# CM_PER register map
Vendor: Texas Instruments
Peripheral module from a debugger description file (folder am437x).
Registers are 32-bit, access per field, no defined reset value unless marked. A register's access mark holds for its fields unless they carry their own. Offsets are as the file gives them; lines under a group give offsets from that group; [hi:lo] are bit positions; {n}, {i} and the like mark numbered series; 'fields as' and 'values as' point back to an identical list; <NAME> marks a mode.

## CM_PER
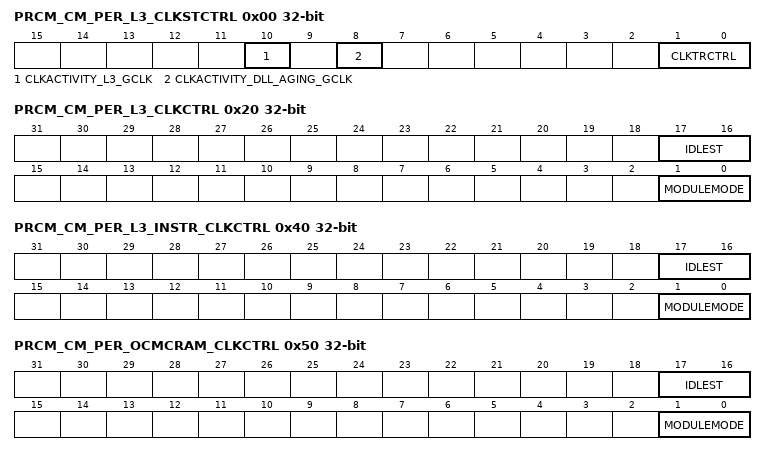
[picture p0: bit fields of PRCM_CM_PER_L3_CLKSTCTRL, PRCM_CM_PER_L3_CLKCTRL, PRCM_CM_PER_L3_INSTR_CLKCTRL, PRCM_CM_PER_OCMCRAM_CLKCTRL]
0x00 PRCM_CM_PER_L3_CLKSTCTRL — This register enables the domain power state transition. It controls the SW supervised clock domain state transition between ON-ACTIVE and ON-INACTIVE states. It also hold one status bit per clock input of the domain.
  [10] CLKACTIVITY_L3_GCLK ro — This field indicates the state of the L3_GCLK clock in the domain.
    1=en_2_0x1 (Corresponding clock is active); 0=en_1_0x0 (Corresponding clock is gated)
  [8] CLKACTIVITY_DLL_AGING_GCLK ro — This field indicates the state of the DLL_AGING_GCLK clock in the domain.
    values as CLKACTIVITY_L3_GCLK
  [1:0] CLKTRCTRL rw — Controls the clock state transition of the L3 clock domain.
    3=en_4_0x3 (Reserved); 2=en_3_0x2 (SW_WKUP: Start a software forced wake-up transition on the domain.); 1=en_2_0x1 (SW_SLEEP: Start a software forced sleep transition on the domain.); 0=en_1_0x0 (NO_SLEEP: Sleep transition cannot be initiated. Wakeup transition may however occur.)
0x20 PRCM_CM_PER_L3_CLKCTRL — This register manages the L3 Interconnect clocks.
  [17:16] IDLEST ro — Module idle status.
    3=en_4_0x3 (Module is disabled and cannot be accessed); 2=en_3_0x2 (Module is in Idle mode (only OCP part). It is functional if using separate functional clock); 1=en_2_0x1 (Module is performing transition: wakeup, or sleep, or sleep abortion); 0=en_1_0x0 (Module is fully functional, including OCP)
  [1:0] MODULEMODE rw — Control the way mandatory clocks are managed.
    3=en_4_0x3 (Reserved); 2=en_3_0x2 (Module is explicitly enabled. Interface clock (if not used for functions) may be gated according to the clock domain state. Functional clocks are guarantied to stay present. As long as in this configuration, power domain sleep transition cannot happen.); 1=en_2_0x1 (Reserved); 0=en_1_0x0 (Module is disable by SW. Any OCP access to module results in an error, except if resulting from a module wakeup (asynchronous wakeup).)
0x40 PRCM_CM_PER_L3_INSTR_CLKCTRL — This register manages the L3 INSTR clocks.
  fields as PRCM_CM_PER_L3_CLKCTRL
0x50 PRCM_CM_PER_OCMCRAM_CLKCTRL — This register manages the OCMC clocks.
  fields as PRCM_CM_PER_L3_CLKCTRL
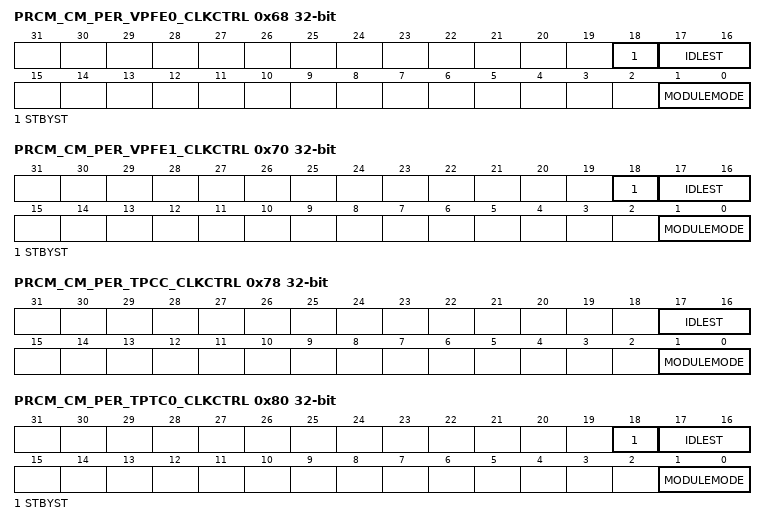
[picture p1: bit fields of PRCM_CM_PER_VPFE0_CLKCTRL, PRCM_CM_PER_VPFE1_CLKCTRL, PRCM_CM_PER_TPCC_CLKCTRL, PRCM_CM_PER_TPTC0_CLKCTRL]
0x68 PRCM_CM_PER_VPFE0_CLKCTRL — This register manages the VPFE0 clocks.
  [18] STBYST ro — Module standby status.
    1=en_2_0x1 (Module is in standby); 0=en_1_0x0 (Module is functional (not in standby))
  [17:16] IDLEST ro — Module idle status.
    values as PRCM_CM_PER_L3_CLKCTRL.IDLEST
  [1:0] MODULEMODE rw — Control the way mandatory clocks are managed.
    values as PRCM_CM_PER_L3_CLKCTRL.MODULEMODE
0x70 PRCM_CM_PER_VPFE1_CLKCTRL — This register manages the VPFE1 clocks.
  fields as PRCM_CM_PER_VPFE0_CLKCTRL
0x78 PRCM_CM_PER_TPCC_CLKCTRL — This register manages the TPCC clocks.
  fields as PRCM_CM_PER_L3_CLKCTRL
0x80 PRCM_CM_PER_TPTC0_CLKCTRL — This register manages the TPTC clocks.
  fields as PRCM_CM_PER_VPFE0_CLKCTRL
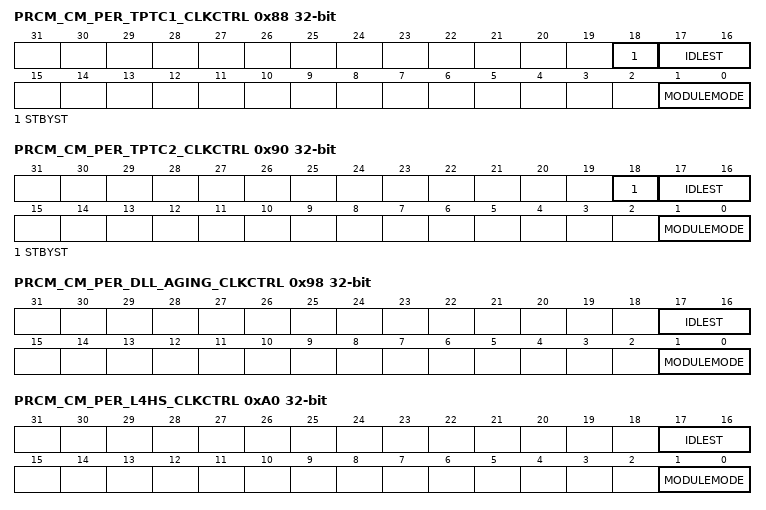
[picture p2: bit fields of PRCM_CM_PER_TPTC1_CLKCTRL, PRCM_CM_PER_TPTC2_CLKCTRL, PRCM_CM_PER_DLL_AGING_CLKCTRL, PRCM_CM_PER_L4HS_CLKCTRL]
0x88 PRCM_CM_PER_TPTC1_CLKCTRL — This register manages the TPTC1 clocks.
  fields as PRCM_CM_PER_VPFE0_CLKCTRL
0x90 PRCM_CM_PER_TPTC2_CLKCTRL — This register manages the TPTC2 clocks.
  fields as PRCM_CM_PER_VPFE0_CLKCTRL
0x98 PRCM_CM_PER_DLL_AGING_CLKCTRL — This register manages the DLL_AGING clocks.
  fields as PRCM_CM_PER_L3_CLKCTRL
0xA0 PRCM_CM_PER_L4HS_CLKCTRL — This register manages the L4 Fast clocks.
  fields as PRCM_CM_PER_L3_CLKCTRL
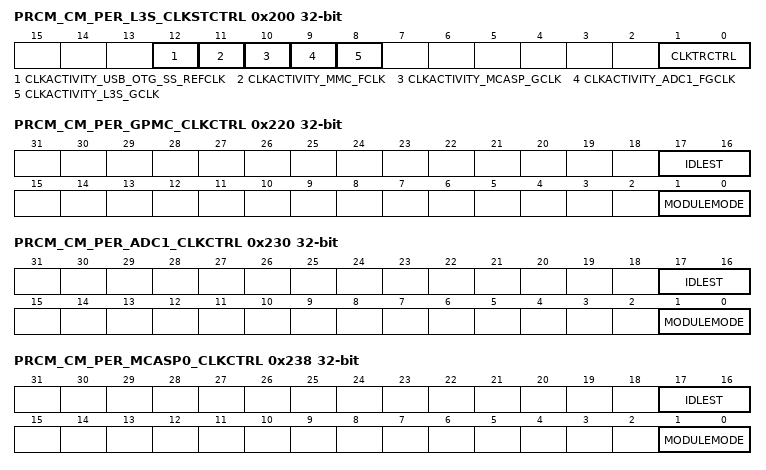
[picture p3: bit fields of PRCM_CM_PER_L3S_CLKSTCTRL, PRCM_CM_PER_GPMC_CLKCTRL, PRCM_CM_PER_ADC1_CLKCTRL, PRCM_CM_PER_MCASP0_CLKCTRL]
0x200 PRCM_CM_PER_L3S_CLKSTCTRL — This register enables the domain power state transition. It controls the SW supervised clock domain state transition between ON-ACTIVE and ON-INACTIVE states. It also hold one status bit per clock input of the domain.
  [12] CLKACTIVITY_USB_OTG_SS_REFCLK ro — This field indicates the state of the USB_OTG_SS_REFCLK clock in the domain.
    values as PRCM_CM_PER_L3_CLKSTCTRL.CLKACTIVITY_L3_GCLK
  [11] CLKACTIVITY_MMC_FCLK ro — This field indicates the state of the MMC_GCLK clock in the domain.
    values as PRCM_CM_PER_L3_CLKSTCTRL.CLKACTIVITY_L3_GCLK
  [10] CLKACTIVITY_MCASP_GCLK ro — This field indicates the state of the MCASP_GCLK clock in the domain.
    values as PRCM_CM_PER_L3_CLKSTCTRL.CLKACTIVITY_L3_GCLK
  [9] CLKACTIVITY_ADC1_FGCLK ro — This register manages the ADC1 clocks.
    values as PRCM_CM_PER_L3_CLKSTCTRL.CLKACTIVITY_L3_GCLK
  [8] CLKACTIVITY_L3S_GCLK ro — This field indicates the state of the L3S_GCLK clock in the domain.
    values as PRCM_CM_PER_L3_CLKSTCTRL.CLKACTIVITY_L3_GCLK
  [1:0] CLKTRCTRL rw — Controls the clock state transition of the L3 Slow clock domain.
    values as PRCM_CM_PER_L3_CLKSTCTRL.CLKTRCTRL
0x220 PRCM_CM_PER_GPMC_CLKCTRL — This register manages the GPMC clocks.
  fields as PRCM_CM_PER_L3_CLKCTRL
0x230 PRCM_CM_PER_ADC1_CLKCTRL — This register manages the ADC1 clocks.
  fields as PRCM_CM_PER_L3_CLKCTRL
0x238 PRCM_CM_PER_MCASP0_CLKCTRL — This register manages the MCASP0 clocks.
  fields as PRCM_CM_PER_L3_CLKCTRL
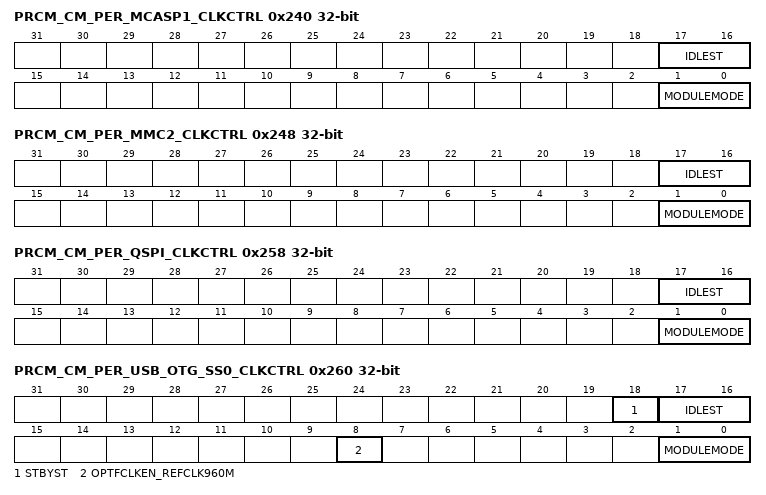
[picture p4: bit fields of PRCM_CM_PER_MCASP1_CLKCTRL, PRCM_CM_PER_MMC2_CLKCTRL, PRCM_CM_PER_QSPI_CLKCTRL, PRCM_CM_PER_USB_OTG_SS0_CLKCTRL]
0x240 PRCM_CM_PER_MCASP1_CLKCTRL — This register manages the MCASP1 clocks.
  fields as PRCM_CM_PER_L3_CLKCTRL
0x248 PRCM_CM_PER_MMC2_CLKCTRL — This register manages the MMC2 clocks.
  fields as PRCM_CM_PER_L3_CLKCTRL
0x258 PRCM_CM_PER_QSPI_CLKCTRL — This register manages the QSPI clocks.
  fields as PRCM_CM_PER_L3_CLKCTRL
0x260 PRCM_CM_PER_USB_OTG_SS0_CLKCTRL — This register manages the USB_OTG_SS0 clocks.
  [18] STBYST ro — Module standby status. [[br]][warm reset insensitive]
    values as PRCM_CM_PER_VPFE0_CLKCTRL.STBYST
  [17:16] IDLEST ro — Module idle status. [[br]][warm reset insensitive]
    values as PRCM_CM_PER_L3_CLKCTRL.IDLEST
  [8] OPTFCLKEN_REFCLK960M rw — USB_OTG optional clock control: REFCLK960(960MHz)
    1=en_2_0x1 (Optional functional clock is enabled); 0=en_1_0x0 (Optional functional clock is disabled)
  [1:0] MODULEMODE rw — Control the way mandatory clocks are managed.
    values as PRCM_CM_PER_L3_CLKCTRL.MODULEMODE
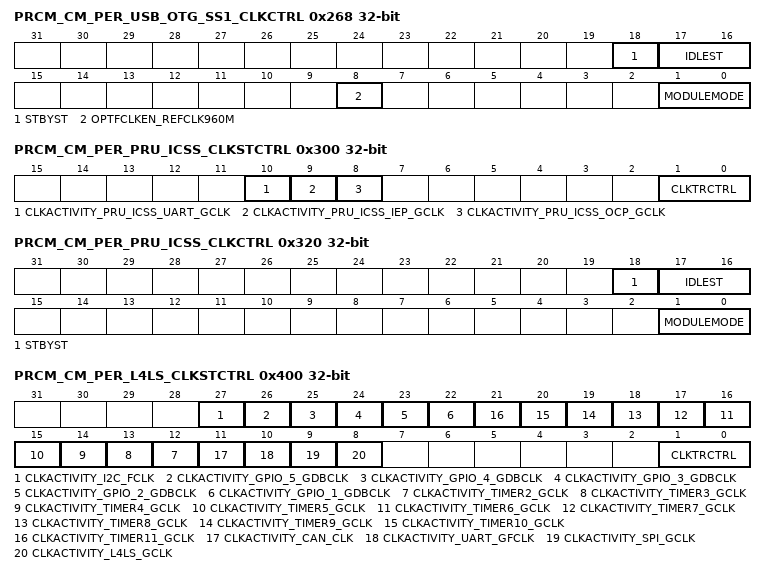
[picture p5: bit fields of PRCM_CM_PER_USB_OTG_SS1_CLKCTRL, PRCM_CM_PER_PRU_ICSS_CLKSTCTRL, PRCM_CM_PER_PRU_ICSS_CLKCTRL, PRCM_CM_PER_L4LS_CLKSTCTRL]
0x268 PRCM_CM_PER_USB_OTG_SS1_CLKCTRL — This register manages the USB_OTG_SS1 clocks.
  fields as PRCM_CM_PER_USB_OTG_SS0_CLKCTRL
0x300 PRCM_CM_PER_PRU_ICSS_CLKSTCTRL — This register enables the clock domain state transition. It controls the SW supervised clock domain state transition between ON-ACTIVE and ON-INACTIVE states. It also hold one status bit per clock input of the domain.
  [10] CLKACTIVITY_PRU_ICSS_UART_GCLK ro — This field indicates the state of the PRU-ICSS UART clock in the domain.
    values as PRCM_CM_PER_L3_CLKSTCTRL.CLKACTIVITY_L3_GCLK
  [9] CLKACTIVITY_PRU_ICSS_IEP_GCLK ro — This field indicates the state of the PRU-ICSS IEP clock in the domain.
    values as PRCM_CM_PER_L3_CLKSTCTRL.CLKACTIVITY_L3_GCLK
  [8] CLKACTIVITY_PRU_ICSS_OCP_GCLK ro — This field indicates the state of the PRU-ICSS OCP clock in the domain.
    values as PRCM_CM_PER_L3_CLKSTCTRL.CLKACTIVITY_L3_GCLK
  [1:0] CLKTRCTRL rw — Controls the clock state transition of the PRU-ICSS OCP clock domain.
    values as PRCM_CM_PER_L3_CLKSTCTRL.CLKTRCTRL
0x320 PRCM_CM_PER_PRU_ICSS_CLKCTRL — This register manages the ICSS clocks.
  fields as PRCM_CM_PER_VPFE0_CLKCTRL
0x400 PRCM_CM_PER_L4LS_CLKSTCTRL — This register enables the domain power state transition. It controls the SW supervised clock domain state transition between ON-PER and ON-INPER states. It also hold one status bit per clock input of the domain.
  [27] CLKACTIVITY_I2C_FCLK ro — This field indicates the state of the I2C _FCLK clock in the domain.
    values as PRCM_CM_PER_L3_CLKSTCTRL.CLKACTIVITY_L3_GCLK
  [26] CLKACTIVITY_GPIO_5_GDBCLK ro — This field indicates the state of the GPIO5_GDBCLK clock in the domain.
    values as PRCM_CM_PER_L3_CLKSTCTRL.CLKACTIVITY_L3_GCLK
  [25] CLKACTIVITY_GPIO_4_GDBCLK ro — This field indicates the state of the GPIO4_GDBCLK clock in the domain.
    values as PRCM_CM_PER_L3_CLKSTCTRL.CLKACTIVITY_L3_GCLK
  [24] CLKACTIVITY_GPIO_3_GDBCLK ro — This field indicates the state of the GPIO3_GDBCLK clock in the domain.
    values as PRCM_CM_PER_L3_CLKSTCTRL.CLKACTIVITY_L3_GCLK
  [23] CLKACTIVITY_GPIO_2_GDBCLK ro — This field indicates the state of the GPIO2_ GDBCLK clock in the domain.
    values as PRCM_CM_PER_L3_CLKSTCTRL.CLKACTIVITY_L3_GCLK
  [22] CLKACTIVITY_GPIO_1_GDBCLK ro — This field indicates the state of the GPIO1_GDBCLK clock in the domain.
    values as PRCM_CM_PER_L3_CLKSTCTRL.CLKACTIVITY_L3_GCLK
  [n+10] CLKACTIVITY_TIMER{n}_GCLK ro (n=2..11) — This field indicates the state of the TIMER{n} CLKTIMER clock in the domain.
    values as PRCM_CM_PER_L3_CLKSTCTRL.CLKACTIVITY_L3_GCLK
  [11] CLKACTIVITY_CAN_CLK ro — This field indicates the state of the CAN_CLK clock in the domain.
    values as PRCM_CM_PER_L3_CLKSTCTRL.CLKACTIVITY_L3_GCLK
  [10] CLKACTIVITY_UART_GFCLK ro — This field indicates the state of the UART_GFCLK clock in the domain.
    values as PRCM_CM_PER_L3_CLKSTCTRL.CLKACTIVITY_L3_GCLK
  [9] CLKACTIVITY_SPI_GCLK ro — This field indicates the state of the SPI_GCLK clock in the domain.
    values as PRCM_CM_PER_L3_CLKSTCTRL.CLKACTIVITY_L3_GCLK
  [8] CLKACTIVITY_L4LS_GCLK ro — This field indicates the state of the L4LS_GCLK clock in the domain.
    values as PRCM_CM_PER_L3_CLKSTCTRL.CLKACTIVITY_L3_GCLK
  [1:0] CLKTRCTRL rw — Controls the clock state transition of the L4 SLOW clock domain in PER power domain.
    values as PRCM_CM_PER_L3_CLKSTCTRL.CLKTRCTRL
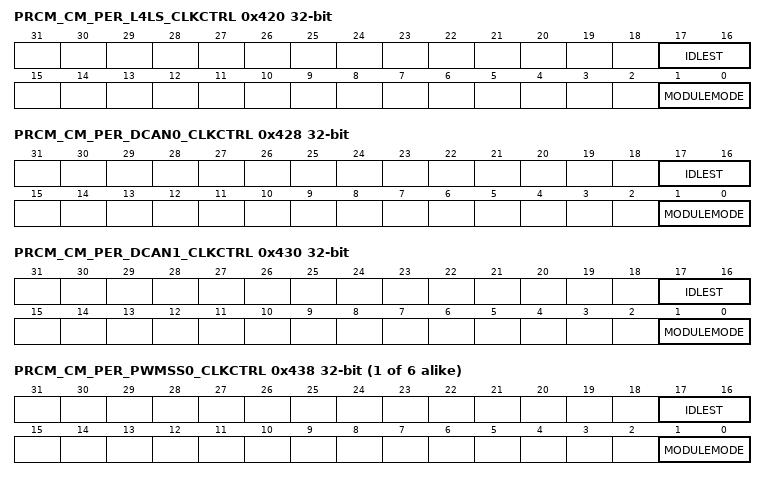
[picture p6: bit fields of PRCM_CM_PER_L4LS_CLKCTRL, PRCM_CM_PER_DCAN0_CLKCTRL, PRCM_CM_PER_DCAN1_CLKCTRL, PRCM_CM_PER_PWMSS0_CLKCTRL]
0x420 PRCM_CM_PER_L4LS_CLKCTRL — This register manages the L4LS clocks.
  fields as PRCM_CM_PER_L3_CLKCTRL
0x428 PRCM_CM_PER_DCAN0_CLKCTRL — This register manages the DCAN0 clocks.
  fields as PRCM_CM_PER_L3_CLKCTRL
0x430 PRCM_CM_PER_DCAN1_CLKCTRL — This register manages the DCAN1 clocks.
  fields as PRCM_CM_PER_L3_CLKCTRL
{0x438+8i} PRCM_CM_PER_PWMSS{i}_CLKCTRL (i=0..5) — This register manages the PWMSS{i} clocks.
  fields as PRCM_CM_PER_L3_CLKCTRL
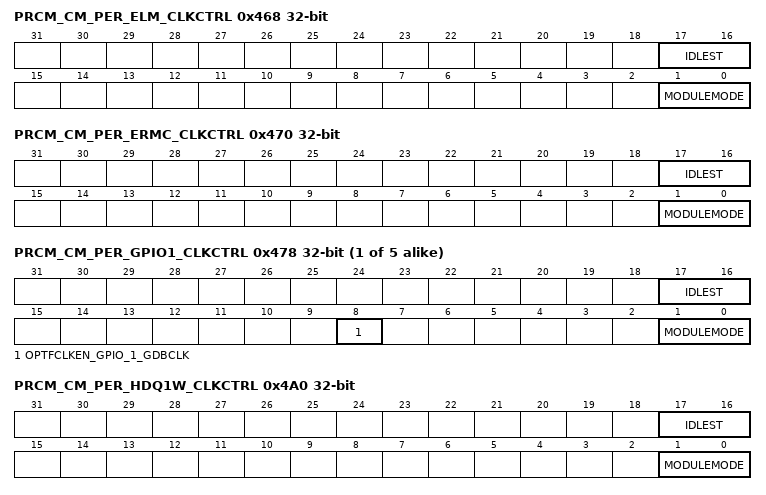
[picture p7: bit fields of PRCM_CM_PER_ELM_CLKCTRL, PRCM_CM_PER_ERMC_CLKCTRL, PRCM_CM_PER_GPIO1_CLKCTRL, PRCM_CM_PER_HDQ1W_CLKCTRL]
0x468 PRCM_CM_PER_ELM_CLKCTRL — This register manages the ELM clocks.
  fields as PRCM_CM_PER_L3_CLKCTRL
0x470 PRCM_CM_PER_ERMC_CLKCTRL — This register manages the ERMC clocks.
  fields as PRCM_CM_PER_L3_CLKCTRL
{0x470+8i} PRCM_CM_PER_GPIO{i}_CLKCTRL (i=1..5) — This register manages the GPIO{i} clocks.
  [17:16] IDLEST ro — Module idle status.
    values as PRCM_CM_PER_L3_CLKCTRL.IDLEST
  [8] OPTFCLKEN_GPIO_{i}_GDBCLK rw — Optional functional clock control.
    values as PRCM_CM_PER_USB_OTG_SS0_CLKCTRL.OPTFCLKEN_REFCLK960M
  [1:0] MODULEMODE rw — Control the way mandatory clocks are managed.
    values as PRCM_CM_PER_L3_CLKCTRL.MODULEMODE
0x4A0 PRCM_CM_PER_HDQ1W_CLKCTRL — This register manages the HDQ1W clocks.
  fields as PRCM_CM_PER_L3_CLKCTRL
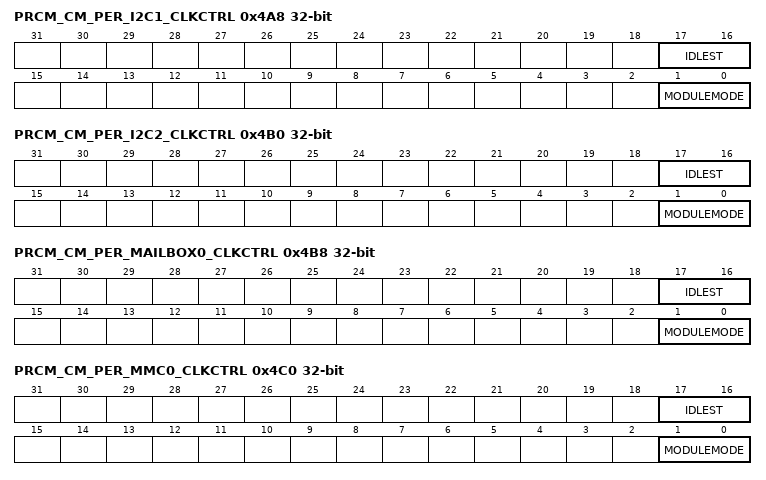
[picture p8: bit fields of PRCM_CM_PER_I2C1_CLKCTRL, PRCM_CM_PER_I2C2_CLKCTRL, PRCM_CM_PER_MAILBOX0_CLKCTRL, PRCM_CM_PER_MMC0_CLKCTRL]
0x4A8 PRCM_CM_PER_I2C1_CLKCTRL — This register manages the I2C1 clocks.
  fields as PRCM_CM_PER_L3_CLKCTRL
0x4B0 PRCM_CM_PER_I2C2_CLKCTRL — This register manages the I2C2 clocks.
  fields as PRCM_CM_PER_L3_CLKCTRL
0x4B8 PRCM_CM_PER_MAILBOX0_CLKCTRL — This register manages the MAILBOX0 clocks.
  fields as PRCM_CM_PER_L3_CLKCTRL
0x4C0 PRCM_CM_PER_MMC0_CLKCTRL — This register manages the MMC0 clocks.
  fields as PRCM_CM_PER_L3_CLKCTRL
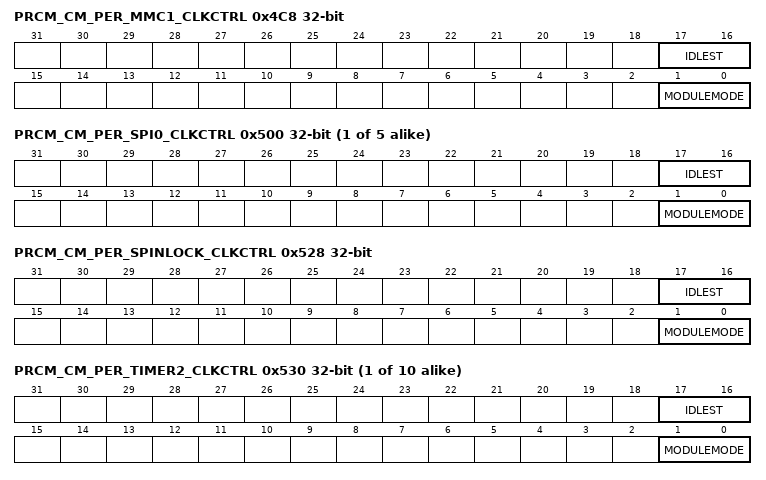
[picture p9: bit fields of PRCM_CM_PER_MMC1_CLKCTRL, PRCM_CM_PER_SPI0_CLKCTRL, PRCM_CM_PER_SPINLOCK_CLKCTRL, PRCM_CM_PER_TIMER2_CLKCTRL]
0x4C8 PRCM_CM_PER_MMC1_CLKCTRL — This register manages the MMC1 clocks.
  fields as PRCM_CM_PER_L3_CLKCTRL
{0x500+8i} PRCM_CM_PER_SPI{i}_CLKCTRL (i=0..4) — This register manages the SPI{i} clocks.
  fields as PRCM_CM_PER_L3_CLKCTRL
0x528 PRCM_CM_PER_SPINLOCK_CLKCTRL — This register manages the SPINLOCK clocks.
  fields as PRCM_CM_PER_L3_CLKCTRL
{0x520+8i} PRCM_CM_PER_TIMER{i}_CLKCTRL (i=2..11) — This register manages the TIMER{i} clocks.
  fields as PRCM_CM_PER_L3_CLKCTRL
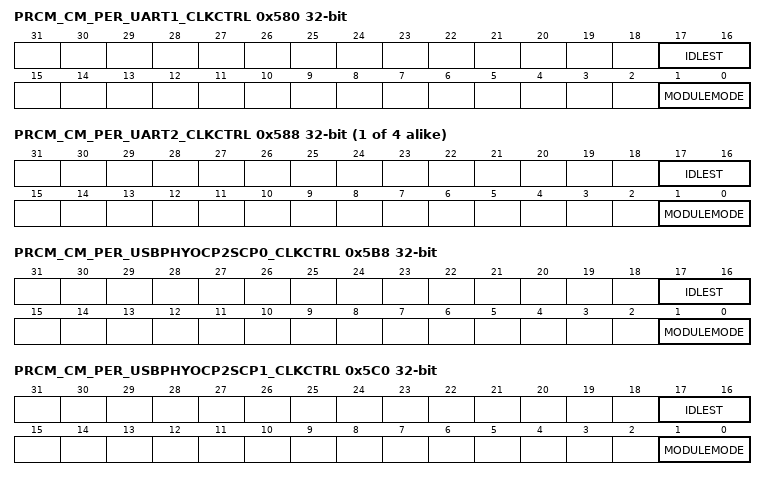
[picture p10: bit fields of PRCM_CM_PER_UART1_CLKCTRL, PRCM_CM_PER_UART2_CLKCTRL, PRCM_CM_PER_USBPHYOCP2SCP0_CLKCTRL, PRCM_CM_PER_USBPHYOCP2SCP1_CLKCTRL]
0x580 PRCM_CM_PER_UART1_CLKCTRL — This register manages the IART1 clocks.
  fields as PRCM_CM_PER_L3_CLKCTRL
{0x578+8i} PRCM_CM_PER_UART{i}_CLKCTRL (i=2..5) — This register manages the UART{i} clocks.
  fields as PRCM_CM_PER_L3_CLKCTRL
0x5B8 PRCM_CM_PER_USBPHYOCP2SCP0_CLKCTRL — This register manages the USBPHYOCP2SCP0 clocks and the optional clock of USB PHY.
  [17:16] IDLEST ro — Module idle status. [[br]][warm reset insensitive]
    values as PRCM_CM_PER_L3_CLKCTRL.IDLEST
  [1:0] MODULEMODE rw — Control the way mandatory clocks are managed.
    values as PRCM_CM_PER_L3_CLKCTRL.MODULEMODE
0x5C0 PRCM_CM_PER_USBPHYOCP2SCP1_CLKCTRL — This register manages the USBPHYOCP2SCP1 clocks and the optional clock of USB PHY.
  fields as PRCM_CM_PER_USBPHYOCP2SCP0_CLKCTRL
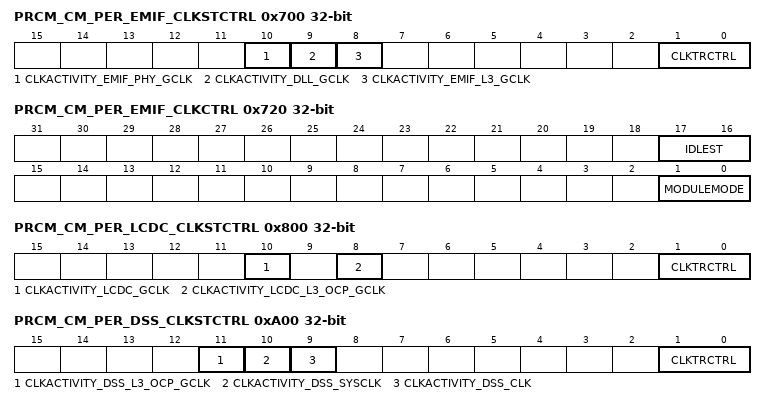
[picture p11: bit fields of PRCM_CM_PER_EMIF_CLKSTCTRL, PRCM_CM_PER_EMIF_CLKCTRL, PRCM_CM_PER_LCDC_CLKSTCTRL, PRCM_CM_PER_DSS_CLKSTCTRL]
0x700 PRCM_CM_PER_EMIF_CLKSTCTRL — This register enables the clock domain state transition. It controls the SW supervised clock domain state transition between ON-ACTIVE and ON-INACTIVE states. It also hold one status bit per clock input of the domain.
  [10] CLKACTIVITY_EMIF_PHY_GCLK ro — This field indicates the state of the EMIF PHY clock in the domain.
    values as PRCM_CM_PER_L3_CLKSTCTRL.CLKACTIVITY_L3_GCLK
  [9] CLKACTIVITY_DLL_GCLK ro — This field indicates the state of the DLL clock in the domain.
    values as PRCM_CM_PER_L3_CLKSTCTRL.CLKACTIVITY_L3_GCLK
  [8] CLKACTIVITY_EMIF_L3_GCLK ro — This field indicates the state of the EMIF L3 clock in the domain.
    values as PRCM_CM_PER_L3_CLKSTCTRL.CLKACTIVITY_L3_GCLK
  [1:0] CLKTRCTRL rw — Controls the clock state transition of the ICSS OCP clock domain.
    values as PRCM_CM_PER_L3_CLKSTCTRL.CLKTRCTRL
0x720 PRCM_CM_PER_EMIF_CLKCTRL — This register manages the EMIF clocks.
  fields as PRCM_CM_PER_L3_CLKCTRL
0x728 PRCM_CM_PER_DLL_CLKCTRL — This register manages the DLL clock.
  [8] OPTFCLKEN_DLL_CLK rw — Optional functional clock control.
    1=en_2_0x1 (Optional functional clock is enabled. DLL_CLK is garantied to not be gated if already running.); 0=en_1_0x0 (Optional functional clock is disabled. DLL_CLK can be gated when EMIF domain performs sleep transition)
0x800 PRCM_CM_PER_LCDC_CLKSTCTRL — This register enables the clock domain state transition. It controls the SW supervised clock domain state transition between ON-ACTIVE and ON-INACTIVE states. It also hold one status bit per clock input of the domain.
  [10] CLKACTIVITY_LCDC_GCLK ro — This field indicates the state of the LCD clock in the domain.
    values as PRCM_CM_PER_L3_CLKSTCTRL.CLKACTIVITY_L3_GCLK
  [8] CLKACTIVITY_LCDC_L3_OCP_GCLK ro — This field indicates the state of the LCDC L3 OCP clock in the domain.
    values as PRCM_CM_PER_L3_CLKSTCTRL.CLKACTIVITY_L3_GCLK
  [1:0] CLKTRCTRL rw — Controls the clock state transition of the LCDC OCP clock domain.
    values as PRCM_CM_PER_L3_CLKSTCTRL.CLKTRCTRL
0xA00 PRCM_CM_PER_DSS_CLKSTCTRL — This register enables the clock domain state transition. It controls the SW supervised clock domain state transition between ON-ACTIVE and ON-INACTIVE states. It also hold one status bit per clock input of the domain.
  [11] CLKACTIVITY_DSS_L3_OCP_GCLK ro — This field indicates the state of the DSS L3 OCP clock in the domain.
    values as PRCM_CM_PER_L3_CLKSTCTRL.CLKACTIVITY_L3_GCLK
  [10] CLKACTIVITY_DSS_SYSCLK ro — This field indicates the state of the DSS SYSCLK clock in the domain.
    values as PRCM_CM_PER_L3_CLKSTCTRL.CLKACTIVITY_L3_GCLK
  [9] CLKACTIVITY_DSS_CLK ro — This field indicates the state of the DSS CLK clock in the domain.
    values as PRCM_CM_PER_L3_CLKSTCTRL.CLKACTIVITY_L3_GCLK
  [1:0] CLKTRCTRL rw — Controls the clock state transition of the DSS OCP clock domain.
    values as PRCM_CM_PER_L3_CLKSTCTRL.CLKTRCTRL
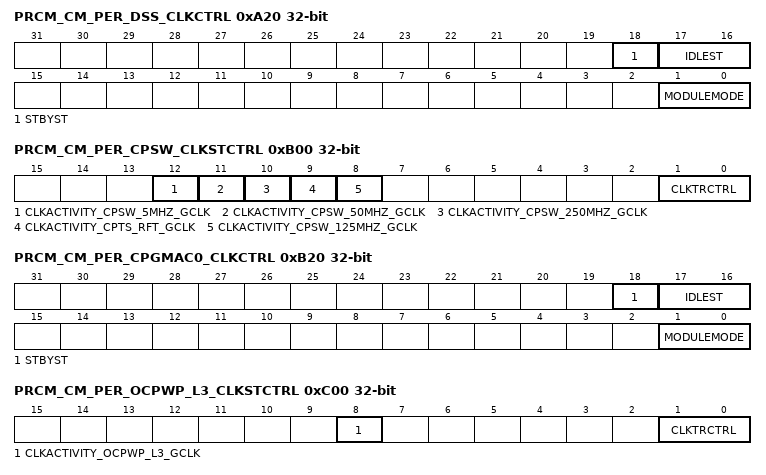
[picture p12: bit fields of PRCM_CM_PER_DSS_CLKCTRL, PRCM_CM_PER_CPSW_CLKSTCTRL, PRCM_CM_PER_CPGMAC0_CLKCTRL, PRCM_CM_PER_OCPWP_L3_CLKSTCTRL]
0xA20 PRCM_CM_PER_DSS_CLKCTRL — This register manages the DSS clocks.
  fields as PRCM_CM_PER_VPFE0_CLKCTRL
0xB00 PRCM_CM_PER_CPSW_CLKSTCTRL — This register enables the clock domain state transition. It controls the SW supervised clock domain state transition between ON-ACTIVE and ON-INACTIVE states. It also hold one status bit per clock input of the domain.
  [12] CLKACTIVITY_CPSW_5MHZ_GCLK ro — This field indicates the state of the CPSW_5MHZ_GCLK clock in the domain.
    values as PRCM_CM_PER_L3_CLKSTCTRL.CLKACTIVITY_L3_GCLK
  [11] CLKACTIVITY_CPSW_50MHZ_GCLK ro — This field indicates the state of the CPSW_50MHZ_GCLK clock in the domain.
    values as PRCM_CM_PER_L3_CLKSTCTRL.CLKACTIVITY_L3_GCLK
  [10] CLKACTIVITY_CPSW_250MHZ_GCLK ro — This field indicates the state of the CPSW_250MHZ_GCLK clock in the domain.
    values as PRCM_CM_PER_L3_CLKSTCTRL.CLKACTIVITY_L3_GCLK
  [9] CLKACTIVITY_CPTS_RFT_GCLK ro — This field indicates the state of the CLKACTIVITY_CPTS_RFT_GCLK clock in the domain.
    values as PRCM_CM_PER_L3_CLKSTCTRL.CLKACTIVITY_L3_GCLK
  [8] CLKACTIVITY_CPSW_125MHZ_GCLK ro — This field indicates the state of the CPSW 125 MHz OCP clock in the domain.
    values as PRCM_CM_PER_L3_CLKSTCTRL.CLKACTIVITY_L3_GCLK
  [1:0] CLKTRCTRL rw — Controls the clock state transition of the CPSW OCP clock domain.
    values as PRCM_CM_PER_L3_CLKSTCTRL.CLKTRCTRL
0xB20 PRCM_CM_PER_CPGMAC0_CLKCTRL — This register manages the CPSW clocks.
  [18] STBYST ro — Module standby status. [[br]]This bit is warm reset insensitive when CPSW RESET_ISO is enabled
    values as PRCM_CM_PER_VPFE0_CLKCTRL.STBYST
  [17:16] IDLEST ro — Module idle status. [[br]]This bit is warm reset insensitive when CPSW RESET_ISO is enabled
    values as PRCM_CM_PER_L3_CLKCTRL.IDLEST
  [1:0] MODULEMODE rw — Control the way mandatory clocks are managed. [[br]]This bit is warm reset insensitive when CPSW RESET_ISO is enabled
    values as PRCM_CM_PER_L3_CLKCTRL.MODULEMODE
0xC00 PRCM_CM_PER_OCPWP_L3_CLKSTCTRL — This register enables the domain power state transition. It controls the SW supervised clock domain state transition between ON-ACTIVE and ON-INACTIVE states. It also hold one status bit per clock input of the domain.
  [8] CLKACTIVITY_OCPWP_L3_GCLK ro — This field indicates the state of the OCPWP L3 clock in the domain.
    1=en_2_0x1 (1); 0=en_1_0x0 (0)
  [1:0] CLKTRCTRL rw — Controls the clock state transition of the OCPWP clock domain.
    values as PRCM_CM_PER_L3_CLKSTCTRL.CLKTRCTRL
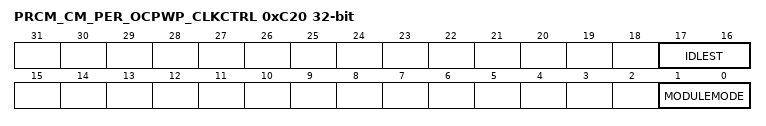
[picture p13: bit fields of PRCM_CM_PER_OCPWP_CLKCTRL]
0xC20 PRCM_CM_PER_OCPWP_CLKCTRL — This register manages the OCPWP clocks.
  fields as PRCM_CM_PER_L3_CLKCTRL
